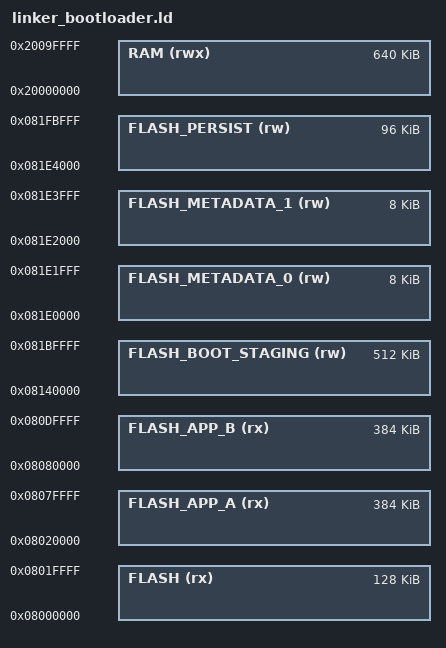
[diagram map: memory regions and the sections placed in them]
/* STM32H5 internal-flash template. Adjust FLASH/RAM sizes and TrustZone split for the exact part. */
MEMORY
{
  FLASH (rx) : ORIGIN = 0x08000000, LENGTH = 128K
  FLASH_APP_A (rx) : ORIGIN = 0x08020000, LENGTH = 384K
  FLASH_APP_B (rx) : ORIGIN = 0x08080000, LENGTH = 384K
  FLASH_BOOT_STAGING (rw) : ORIGIN = 0x08140000, LENGTH = 512K
  FLASH_METADATA_0 (rw) : ORIGIN = 0x081E0000, LENGTH = 8K
  FLASH_METADATA_1 (rw) : ORIGIN = 0x081E2000, LENGTH = 8K
  FLASH_PERSIST (rw) : ORIGIN = 0x081E4000, LENGTH = 96K
  RAM (rwx)  : ORIGIN = 0x20000000, LENGTH = 640K
}
